# IND83215A register map
Series: Verne; File version: A0
CPU: CM0 r0p1, selectable endian, no MPU, no FPU, 4 interrupt priority bits
Registers are 32-bit, read-write, no defined reset value unless marked. A register's access mark holds for its fields unless they carry their own. Offsets are from the block's base; [hi:lo] are bit positions.

## TRIMHV — Trim bits & Control bits in 5V power domain
Base 0x50000900; register names take the prefix TRIMHV_
0x00 RETAIN0 — Retained data 0
  [15:0] RETAIN0 — Firmware scratch register 0. Only reset at power-on (e.g contents retained in Hibernate mode and retained despite any hard or soft resets).
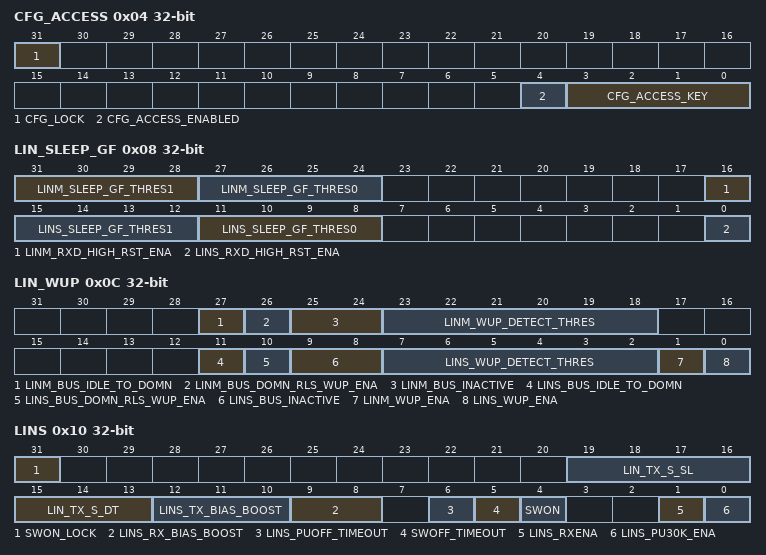
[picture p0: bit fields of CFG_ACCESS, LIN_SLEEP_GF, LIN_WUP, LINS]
0x04 CFG_ACCESS — 5V domain's configuration regs access.
  [31] CFG_LOCK — Set Only bit. Write 1 to this bit to lock CFG_CODE bits.
  [4] CFG_ACCESS_ENABLED ro — A status flag that is set when 5V domain's configuration regs access is enabled
  [3:0] CFG_ACCESS_KEY — Write the value 0xB to this register to enable 'trim access' (which allows write access to various trim settings and production test options). Write any other value to disable trim access.
0x08 LIN_SLEEP_GF — LINS Glitch Filter Configuration in active mode. NOTE:The write operation of this field register takes effect by configuring 'TRIM_HV->CFG.CFG_ACCESS_KEY = 0xB'.
  [31:28] LINM_SLEEP_GF_THRES1 — LINM RXD glitch filter threshold for 0 to 1, detect '1' width of (T_clk_lf*resetvalue = 4us*3 = 12[us]
  [27:24] LINM_SLEEP_GF_THRES0 — LINM RXD glitch filter threshold for 1 to 0, detect '0' width of (T_clk_lf*resetvalue = 4us*3 = 12[us]
  [16] LINM_RXD_HIGH_RST_ENA — Enable signal that LINs RXD glitch filter at sleep mode is asynchronous reset by high of LINs_RXD.
  [15:12] LINS_SLEEP_GF_THRES1 — LINS RXD glitch filter threshold for 0 to 1, detect '1' width of (T_clk_lf*resetvalue = 4us*3 = 12[us]
  [11:8] LINS_SLEEP_GF_THRES0 — LINS RXD glitch filter threshold for 1 to 0, detect '0' width of (T_clk_lf*resetvalue = 4us*3 = 12[us]
  [0] LINS_RXD_HIGH_RST_ENA — Enable signal that LINs RXD glitch filter at sleep mode is asynchronous reset by high of LINs_RXD.
0x0C LIN_WUP — LIN Wakeup Control, NOTE:The write operation of this field register takes effect by configuring 'TRIM_HV->CFG.CFG_ACCESS_KEY = 0xB'.
  [27] LINM_BUS_IDLE_TO_DOMN ro — Dominant Bus Idle Timeout. The bit is set by the lin core if LIN is in hardware mode & the bus is stuck at dominant inactivity state for 4s~10s. Any bus transition will clear this bit. LIN Master's pullup will be disabled when it is set.
  [26] LINM_BUS_DOMN_RLS_WUP_ENA — LIN Master Bus Dominant Release Wakeup Enable. Set to trigger lin wakeup if bus dominant condition is released after BUS_IDLE_TIMEOUT_DOMINANT is detected.
  [25:24] LINM_BUS_INACTIVE — LIN Master Bus Inactivity Time. NOTE: When the chip uses the LINs bus idle detection in pre5v domain(PMU_SFRS->CTRL.PD1V5_ENA_HIBERNATE=0x0), the write operation of this register takes effect by IOCTRLA_SFRS->LIN.UPDATE
  [23:18] LINM_WUP_DETECT_THRES — LIN Master Wakeup Detection Threshold. Threshold setting(LF_CLK_PREDIV clock cycls) of lin wakeup signal. For instace, if target threshold is 150us@LF_CLK_PREDIV=250KHz, WUP_DETECT_THRES = 150/(1000/250)-1. NOTE: When the chip uses the LINs wakeup logic in pre5v domain(PMU_SFRS->CTRL.PD1V5_ENA_HIBERNATE=0x0), the write operation of this register takes effect by IOCTRLA_SFRS->LIN.UPDATE
  [11] LINS_BUS_IDLE_TO_DOMN ro — Dominant Bus Idle Timeout. The bit is set by the lin core if LIN is in hardware mode & the bus is stuck at dominant inactivity state for 4s~10s. Any bus transition will clear this bit. LIN Slave's pullup will be disabled when it is set.
  [10] LINS_BUS_DOMN_RLS_WUP_ENA — LIN Slave Bus Dominant Release Wakeup Enable. Set to trigger lin wakeup if bus dominant condition is released after BUS_IDLE_TIMEOUT_DOMINANT is detected.
  [9:8] LINS_BUS_INACTIVE — LIN Slave Bus Inactivity Time. NOTE: When the chip uses the LINs bus idle detection in pre5v domain(PMU_SFRS->CTRL.PD1V5_ENA_HIBERNATE=0x0), the write operation of this register takes effect by IOCTRLA_SFRS->LIN.UPDATE
  [7:2] LINS_WUP_DETECT_THRES — LIN Slave Wakeup Detection Threshold. Threshold setting(LF_CLK_PREDIV clock cycls) of lin wakeup signal. For instace, if target threshold is 150us@LF_CLK_PREDIV=250KHz, WUP_DETECT_THRES = 150/(1000/250)-1. NOTE: When the chip uses the LINs wakeup logic in pre5v domain(PMU_SFRS->CTRL.PD1V5_ENA_HIBERNATE=0x0), the write operation of this register takes effect by IOCTRLA_SFRS->LIN.UPDATE
  [1] LINM_WUP_ENA — LIN Master Wakeup Enable. it enables the detect of a wakeup signal on the LIN_OUT bus
  [0] LINS_WUP_ENA — LIN Slave Wakeup Enable. it enables the detect of a wakeup signal on the LIN_IN bus
0x10 LINS — LIN slave Pin Control. NOTE:The write operation of this field register takes effect by configuring 'TRIM_HV->CFG.CFG_ACCESS_KEY = 0xB'.
  [31] SWON_LOCK — SWON Lock Bit.
  [19:16] LIN_TX_S_SL — LIN Slave TX driver slew rate select. Slew from 40%*Vbat to 60%*Vbat @Vbat=13V,Cbus=1nF. 0000 -> 1110: 1.07V/us ~ 4.71V/us, step is about 0.26V/us 1111: about 10V/us for fast LIN mode
  [15:13] LIN_TX_S_DT — LIN Slave duty cycle adjust. 0x0: duty cycle = 0.488 0x1: duty cycle = 0.492 0x2: duty cycle = 0.494 0x3: duty cycle = 0.495 0x4: duty cycle = 0.497 0x5: duty cycle = 0.5 0x6: duty cycle = 0.507 0x7: duty cycle = 0.529
  [12:10] LINS_TX_BIAS_BOOST — LIN Slave IO TX Bias select. Select LIN IO TX Pull Down Current. 0x0: ~61 mA 0x1: ~83 mA 0x2: ~105 mA 0x3: ~126 mA
  [9:8] LINS_RX_BIAS_BOOST — adjust rise delay from LIN_IN to Input of LINS Controller. 0x0: 2.323 us 0x1: 1.344 us 0x2: 0.968 us 0x3: 0.767 us
  [6] LINS_PUOFF_TIMEOUT — LINS Pullup Disable in dominant TimeOut condition. Set to disable LINS 30K pullup in case that lin bus is shorted to ground(Bus idle dominant timeout is detected) for saving power. LINS Pullup will be recovered automatically if bus idle dominant timeout is released by any bus activity. Only reset by power-on sequence.
  [5] SWOFF_TIMEOUT — Switch off in dominant TimeOut condition. Set to disconnect lin switch in case that lin bus is shorted to ground(Bus idle dominant timeout is detected) for saving power. LIN Switch will be recovered automatically if bus idle dominant timeout is released by any bus activity. Only reset by power-on sequence.
  [4] SWON — LIN Dual Mode Switch On. Set to enable dual-mode lin switch. Only reset by power-on sequence. This bit can be locked by setting SWON_LOCK.
  [1] LINS_RXENA — LIN receive enable.
  [0] LINS_PU30K_ENA — LIN 30K pullup enable.
0x14 LINM — LIN Master Pin Control. NOTE:The write operation of this field register takes effect by configuring 'TRIM_HV->CFG.CFG_ACCESS_KEY = 0xB'.
  [30:27] LIN_TX_M_SL — LIN Master TX driver slew rate select. Slew from 40%*Vbat to 60%*Vbat @Vbat=13V,Cbus=1nF. 0000 -> 1110: 1.07V/us ~ 4.71V/us, step is about 0.26V/us 1111: about 10V/us for fast LIN mode
  [26:24] LIN_TX_M_DT — LIN Master duty cycle adjust. 0x0: duty cycle = 0.488 0x1: duty cycle = 0.492 0x2: duty cycle = 0.494 0x3: duty cycle = 0.495 0x4: duty cycle = 0.497 0x5: duty cycle = 0.5 0x6: duty cycle = 0.507 0x7: duty cycle = 0.529
  [23:21] LINM_TX_BIAS_BOOST — LIN Master IO TX Bias select. Select LIN IO TX Pull Down Current. 0x0: ~61 mA 0x1: ~83 mA 0x2: ~105 mA 0x3: ~126 mA
  [21:19] LINM_RX_BIAS_BOOST — adjust rise delay from LIN_OUT to Input of LINM Controller. 0x0: 2.323 us 0x1: 1.344 us 0x2: 0.968 us 0x3: 0.767 us
  [7] LINM_PUOFF_TIMEOUT — LINM 1K Pullup disable in dominant TimeOut condition. Set to disable LINM 1K pullup in case that lin bus is shorted to ground(Bus idle dominant timeout is detected) for saving power. LINS 1K Pullup will be recovered automatically if bus idle dominant timeout is released by any bus activity. If this bit is set & SWON = 1, LINM's 30K pullup will be enabled for preventing bus floating. Only reset by power-on sequence.
  [3] LINM_RXENA — LIN receive enable.
  [2] LINM_PU1K_ENA — LIN 1K pullup enable.
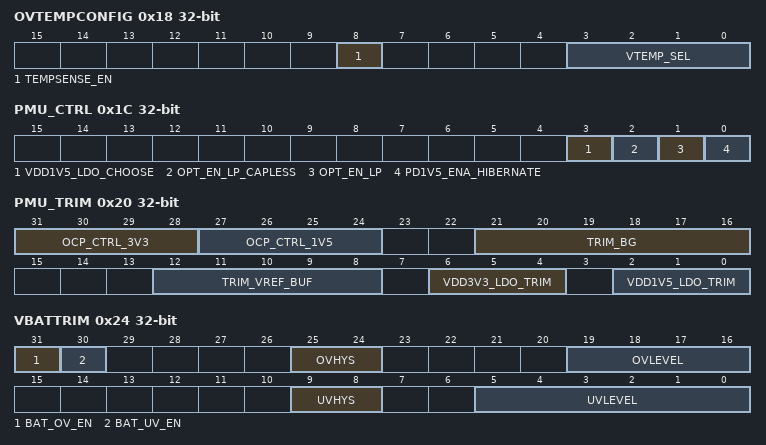
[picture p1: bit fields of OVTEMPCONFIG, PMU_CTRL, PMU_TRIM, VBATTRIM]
0x18 OVTEMPCONFIG — OVTEMP configuration
  [8] TEMPSENSE_EN — enable Temp Sensor Analog Part. Set to enable Temperature Sensor analog circuit.
  [3:0] VTEMP_SEL — Over Temp protect threshold temp trim. Select the OVTEMP threshold level for the monitor. 0x0: Rising: 93.13-Deg; Falling: 79.13-Deg 0x1: Rising: 98.13-Deg; Falling: 84.13-Deg 0x2: Rising: 103.6-Deg; Falling: 89.13-Deg 0x3: Rising: 109.1-Deg; Falling: 94.13-Deg 0x4: Rising: 115.1-Deg; Falling: 99.63-Deg 0x5: Rising: 121.1-Deg; Falling: 105.1-Deg 0x6: Rising: 127.1-Deg; Falling: 111.1-Deg 0x7: Rising: 133.1-Deg; Falling: 117.1-Deg 0x8: Rising: 139.6-Deg; Falling: 123.1-Deg 0x9: Rising: 146.6-Deg; Falling: 129.6-Deg 0xa: Rising: 153.6-Deg; Falling: 136.1-Deg 0xb: Rising: 160.6-Deg; Falling: 142.6-Deg 0xc: Rising: 168.1-Deg; Falling: 149.6-Deg 0xd: Rising: 176.6-Deg; Falling: 157.1-Deg 0xe: Rising: 185.1-Deg; Falling: 164.6-Deg 0xf: Rising: 195.6-Deg; Falling: 172.6-Deg
0x1C PMU_CTRL — PMU Control. NOTE:The write operation of this field register takes effect by configuring 'TRIM_HV->CFG.CFG_ACCESS_KEY = 0xB'.
  [3] VDD1V5_LDO_CHOOSE — 1.5V LDO Mode selection 0x0: choose Capless LDO 0x1: choose Caps LDO
  [2] OPT_EN_LP_CAPLESS — Capless 1.5V ldo low power mode, set 1 to enter low power at Deepsleep mode.
  [1] OPT_EN_LP — Set to enable of low power mode for BG_TOP at Deepsleep Mode.
  [0] PD1V5_ENA_HIBERNATE — enable of 1V5 Power Domain at Hibernate mode. set to enable the 1V5 Power Domain at Hibernate mode, this mode is defined as DEEPSLEEP mode.
0x20 PMU_TRIM — PMU Trim Register. NOTE:The write operation of this field register takes effect by configuring 'TRIM_HV->CFG.CFG_ACCESS_KEY = 0xB'.
  [31:28] OCP_CTRL_3V3 — OCP trim for 3V3 LDO(default 30mA). 0x0: 10.0 mA 0x1: 12.5 mA 0x2: 15.0 mA 0x3: 17.5 mA 0x4: 20.0 mA 0x5: 22.5 mA 0x6: 25.0 mA 0x7: 27.5 mA 0x8: 30.0 mA (default) 0x9: 32.5 mA 0x10: 35.0 mA 0x11: 37.5 mA 0x12: 40.0 mA 0x13: 42.5 mA 0x14: 45.0 mA 0x15: 47.5 mA
  [27:24] OCP_CTRL_1V5 — OCP trim for 1.5V LDO(default 30mA). 0x0: 20.0 mA 0x1: 22.5 mA 0x2: 25.0 mA 0x3: 27.5 mA 0x4: 30.0 mA (default) 0x5: 32.5 mA 0x6: 35.0 mA 0x7: 37.5 mA 0x8: 40.0 mA 0x9: 42.5 mA 0xa: 45.0 mA 0xb: 47.5 mA 0xc: 50.0 mA 0xd: 52.5 mA 0xe: 55.0 mA 0xf: 57.5 mA
  [21:16] TRIM_BG — Trim BandGap. (1) The voltage range before trimming is 1.16797V ~ 1.26337V. (2) The trim ratio 1/1.4811. (3) The voltage is 1.21455V while TRIM_BG == 0x0. at PMU debug mode
  [12:8] TRIM_VREF_BUF — Trim the buffer refernce voltage include VREF_1/VREF_1P1/VREF_0P75/VREF_0P6. (1) The voltage range before trimming is 1.19825V ~ 1.237V. (2) The step is 1.25mV, and the precision of trimming is +- 0.625mV. (3) The voltage is 1.217V while TRIM_VREF_BUF == 0x0. at PMU debug mode
  [6:4] VDD3V3_LDO_TRIM — 3.3V LDO output trim. at PMU debug mode 0x0: 3.37 V(default) 0x1: 2.98 V 0x2: 3.07 V 0x3: 3.16 V 0x4: 3.26 V 0x5: 3.49 V 0x6: 3.62 V 0x7: 3.78 V
  [2:0] VDD1V5_LDO_TRIM — 1.5V LDO Capless output trim. at PMU debug mode 0x0: 1.452 V 0x1: 1.479 V 0x2: 1.509 V 0x3: 1.543 V(default) 0x4: 1.572 V 0x5: 1.604 V 0x6: 1.639 V 0x7: 1.679 V
0x24 VBATTRIM — VBAT Monitor Trim Register
  [31] BAT_OV_EN — Battery Over Voltage Monitor Enable. Set to enable the vbat over voltage monitor analog comparator circuit.
  [30] BAT_UV_EN — Battery Under Voltage Monitor Enable. Set to enable the vbat under voltage monitor analog comparator circuit.
  [25:24] OVHYS — Battery Voltage Monitor Over Voltage Hysterisis Select. Selects the hysterisis level for the Over Voltage monitor. 0x0: 0.359V 0x1: 0.720V 0x2: 1.080V 0x3: 1.440V
  [19:16] OVLEVEL — Battery Voltage Monitor Over Voltage Select. Selects the reference level for the Over Voltage monitor to output one-hot Configuration to Analog Module.(If OVLEVEL>9, the actual analog trim value is the same as default value:OVLEVEL=0x07) 0x0: Over Voltage Threshold- 10'h001: 14.75V 0x1: Over Voltage Threshold- 10'h002: 15.18V 0x2: Over Voltage Threshold- 10'h004: 15.65V 0x3: Over Voltage Threshold- 10'h008: 16.37V 0x4: Over Voltage Threshold- 10'h010: 16.85V 0x5: Over Voltage Threshold- 10'h020: 17.57V 0x6: Over Voltage Threshold- 10'h040: 18.30V 0x7: Over Voltage Threshold- 10'h080: 19.00V 0x8: Over Voltage Threshold- 10'h100: 19.97V 0x9: Over Voltage Threshold- 10'h200: 20.70V
  [9:8] UVHYS — Battery Voltage Monitor Under Voltage Hysterisis Select. Selects the hysterisis level for the Under Voltage monitor. 0x0: 0.475V 0x1: 0.835V 0x2: 1.225V 0x3: 1.635V
  [5:0] UVLEVEL — Battery Voltage Monitor Under Voltage Select. Selects the reference level for the Under Voltage monitor. If UVLEVEL[5:3]>0x04, the actual analog trim value is the same as UVLEVEL=0x0A. The UVLEVEL threshold is mononically increased with the setting. 0x0: Vf: 4.615V 0x1: Vf: 4.685V 0x7: Vf: 5.135V 0x8: Vf: 5.225V 0x9: Vf: 5.135V 0xa: Vf: 5.405V 0xf: Vf: 5.895V 0x10: Vf: 6.015V 0x11: Vf: 6.125V 0x17: Vf: 6.925V 0x18: Vf: 7.075V 0x19: Vf: 7.235V 0x1f: Vf: 8.385V 0x20: Vf: 8.605V 0x21: Vf: 8.845V 0x27: Vf:10.610V
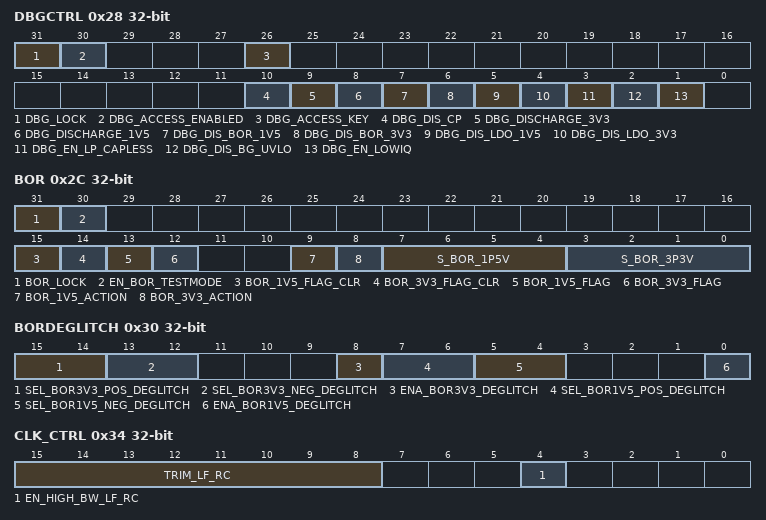
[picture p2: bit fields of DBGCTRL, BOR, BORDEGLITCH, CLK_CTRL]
0x28 DBGCTRL — PMU Debug Control.
  [31] DBG_LOCK — Set Only bit. Set this bit to lock DBG_CODE bits.
  [30] DBG_ACCESS_ENABLED ro — A status flag that is set when debug access is enabled
  [26] DBG_ACCESS_KEY — Write the value 0x5 to this register to enable debug options. Write any other value to disable the debug options.
  [10] DBG_DIS_CP — Set 1, Shut down PRE5V ChargePump, PRE5V=Vzener-Vgs. Only take effect at Debug mode(DBG_TEST = 1) at PMU debug mode
  [9] DBG_DISCHARGE_3V3 — 3V3 LDO Debug Mode: a. Set '0' to test 3V3-LDO function; b. Set '1' to test 3V3-LDO Discharge Circuit.
  [8] DBG_DISCHARGE_1V5 — 1V5 LDO Debug Mode: a. Set '0' to test 1V5-LDO function; b. Set '1' to test 1V5-LDO Discharge Circuit.
  [7] DBG_DIS_BOR_1V5 — Debug Contrl of dis_bor_1v5 at PMU debug mode
  [6] DBG_DIS_BOR_3V3 — Debug Contrl of dis_bor_3v3 at PMU debug mode
  [5] DBG_DIS_LDO_1V5 — Debug Contrl of dis_ldo_1v5 at PMU debug mode.
  [4] DBG_DIS_LDO_3V3 — NOTE:Don't use.Debug Contrl of dis_ldo_3v3 at PMU debug mode
  [3] DBG_EN_LP_CAPLESS — 1.5V ldo low power mode, set 1 to enter low power at PMU debug mode
  [2] DBG_DIS_BG_UVLO — Set to disable of low power mode for UVLO in BG_TOP at PMU debug mode
  [1] DBG_EN_LOWIQ — Set to enable of low power mode for BG_TOP at PMU debug mode
0x2C BOR — BOR configuration.
  [31] BOR_LOCK — Set Only bit. Set this bit to lock BOR_ACTION & S_BOR bits.
  [30] EN_BOR_TESTMODE — BOR Testmode Enable. 0x0: BOR Testmode Disabled: Reference Voltage for BOR is from Band Gap (Functional Mode) 0x1: BOR Testmode Enabled: Reference Voltage for BOR is from gpio1_anaOut (Test Mode
  [15] BOR_1V5_FLAG_CLR — BOR 1v5 clear. Set to clear the 1.5V brownout detected flag
  [14] BOR_3V3_FLAG_CLR wo — BOR 3v3 clear. Set to clear the 3.3V brownout detected flag
  [13] BOR_1V5_FLAG ro — BOR 1v5 flag. Set by the hardware when a brownout of the 1.5V supply is detected.
  [12] BOR_3V3_FLAG ro — BOR 3v3 flag. Set by the hardware when a brownout of the 3.3V supply is detected.
  [9] BOR_1V5_ACTION — BOR 1v5 action. Defines the consequences of brown-out condition on the 1v5 supply being detected by the hardware. NOTE: The write operation will be locked by BOR_SFRS->BOR_LOCK 0x1: IRQ generated 0x0: Hard reset generated
  [8] BOR_3V3_ACTION — BOR 3v3 action. Defines the consequences of brown-out condition on the 3v3 supply being detected by the hardware. NOTE: The write operation will be locked by BOR_SFRS->BOR_LOCK 0x1: IRQ generated 0x0: Hard reset generated
  [7:4] S_BOR_1P5V — BOR 1v5 threshold. Select the BOR threshold voltage level for the 1v5 regulator. Following typical value can be used as reference: NOTE: The write operation of this register takes effect only at trim mode 0x0: Vr: 1.243 V, Vf: 1.218 V, 0x1: Vr: 1.273 V, Vf: 1.243 V, 0x2: Vr: 1.298 V, Vf: 1.273 V, 0x3: Vr: 1.328 V, Vf: 1.298 V, 0x4: Vr: 1.358 V, Vf: 1.328 V, 0x5: Vr: 1.393 V, Vf: 1.363 V, 0x6: Vr: 1.428 V, Vf: 1.393 V, 0x7: Vr: 1.463 V, Vf: 1.428 V, 0x8: Vr: 1.498 V, Vf: 1.468 V, 0x9: Vr: 1.538 V, Vf: 1.503 V, 0xa: Vr: 1.583 V, Vf: 1.548 V, 0xb: Vr: 1.623 V, Vf: 1.588 V, 0xc: Vr: 1.673 V, Vf: 1.633 V, 0xd: Vr: 1.718 V, Vf: 1.683 V, 0xe: Vr: 1.773 V, Vf: 1.733 V, 0xf: Vr: 1.828 V, Vf: 1.788 V,
  [3:0] S_BOR_3P3V — BOR 3v3 threshold. Select the BOR threshold voltage level for the 3v3 regulator, Following typical value can be used as reference: NOTE: The write operation of this register takes effect only at trim mode 0x0: Vr: 2.223 V, Vf: 2.163 V, 0x1: Vr: 2.288 V, Vf: 2.228 V, 0x2: Vr: 2.358 V, Vf: 2.293 V, 0x3: Vr: 2.428 V, Vf: 2.363 V, 0x4: Vr: 2.503 V, Vf: 2.433 V, 0x5: Vr: 2.583 V, Vf: 2.513 V, 0x6: Vr: 2.668 V, Vf: 2.598 V, 0x7: Vr: 2.763 V, Vf: 2.688 V, 0x8: Vr: 2.858 V, Vf: 2.783 V, 0x9: Vr: 2.968 V, Vf: 2.883 V, 0xa: Vr: 3.078 V, Vf: 2.998 V, 0xb: Vr: 3.203 V, Vf: 3.118 V, 0xc: Vr: 3.338 V, Vf: 3.248 V, 0xd: Vr: 3.483 V, Vf: 3.388 V, 0xe: Vr: 3.638 V, Vf: 3.543 V, 0xf: Vr: 3.813 V, Vf: 3.708 V,
0x30 BORDEGLITCH
  [15:14] SEL_BOR3V3_POS_DEGLITCH — select the deglitch width of BOR3V3 posedge. 0x0: 16us Selected 0x1: 32us Selected 0x2: 64us Selected 0x3: 128us Selected
  [13:12] SEL_BOR3V3_NEG_DEGLITCH — select the deglitch width of BOR3V3 negedge. 0x0: 16us Selected 0x1: 32us Selected 0x2: 64us Selected 0x3: 128us Selected
  [8] ENA_BOR3V3_DEGLITCH — enable of BOR3V3 deglitch.
  [7:6] SEL_BOR1V5_POS_DEGLITCH — select the deglitch width of BOR1V5 posedge. 0x0: 16us Selected 0x1: 32us Selected 0x2: 64us Selected 0x3: 128us Selected
  [5:4] SEL_BOR1V5_NEG_DEGLITCH — select the deglitch width of BOR1V5 negedge. 0x0: 16us Selected 0x1: 32us Selected 0x2: 64us Selected 0x3: 128us Selected
  [0] ENA_BOR1V5_DEGLITCH — enable of BOR1V5 deglitch.
0x34 CLK_CTRL — Clock controls for 5V(always on) domain.
  [15:8] TRIM_LF_RC — LF RC oscillator trim. Following value only used as a reference:(the trim freq is non-linear) 0x0: freq(250k)=141.1Khz 0xa2: freq(250k)=250.0Khz 0xa4: freq(250k)=256.0Khz 0xff: freq(250k)=441.7Khz
  [4] EN_HIGH_BW_LF_RC — set to enable to increase internal comparator bandwidth
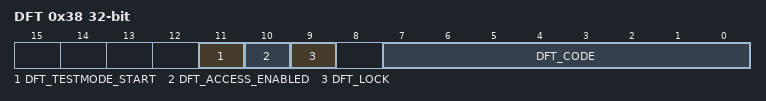
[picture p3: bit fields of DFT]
0x38 DFT
  [11] DFT_TESTMODE_START wo — Puts the ASIC into DFT testmode. Once the start bit is set, the I/O configuration will switch from Application mode to DFT Test Mode. The General Purpose I/Os will be configured as a JTAG interface. Once Test Mode is enabled, the ASIC will be boundary terminated and the processor will lose the ability to communicate with any ASIC peripherals. A chip power cycle is required to get out of the DFT test mode. Test Mode Enable state.
  [10] DFT_ACCESS_ENABLED ro — A status flag that is set when DFT access is enabled.
  [9] DFT_LOCK — Set Only bit. Write 1 to this bit to lock DFT_CODE config bits.
  [7:0] DFT_CODE wo — Write the value 0x1C to this register to Unlock 'Scan Test Mode'.
